# PIC32MZ2048EFM144 register map
Registers are 32-bit, access not given, reset 0x0 unless marked. A register's access mark holds for its fields unless they carry their own. Offsets are from the block's base; [hi:lo] are bit positions; 'fields as' and 'values as' point back to an identical list.

## TMR6 — TMR6 peripheral
Base 0xBF840A00
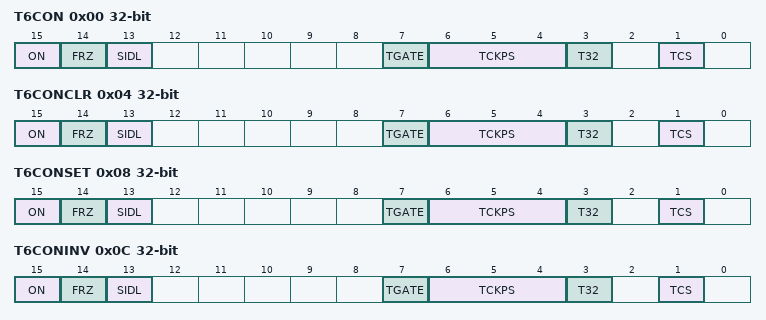
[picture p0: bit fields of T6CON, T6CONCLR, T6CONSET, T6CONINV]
0x00 T6CON
  [15] ON, [14] FRZ, [13] SIDL, [7] TGATE, [6:4] TCKPS, [3] T32, [1] TCS
0x04 T6CONCLR
  fields as T6CON
0x08 T6CONSET
  fields as T6CON
0x0C T6CONINV
  fields as T6CON
0x10 TMR6
0x14 TMR6CLR
  [31:0] TMR6
0x18 TMR6SET
  [31:0] TMR6
0x1C TMR6INV
  [31:0] TMR6
0x20 PR6 reset 0xFFFF
0x24 PR6CLR
  [31:0] PR6
0x28 PR6SET
  [31:0] PR6
0x2C PR6INV
  [31:0] PR6

## TMR7 — TMR7 peripheral
Base 0xBF840C00
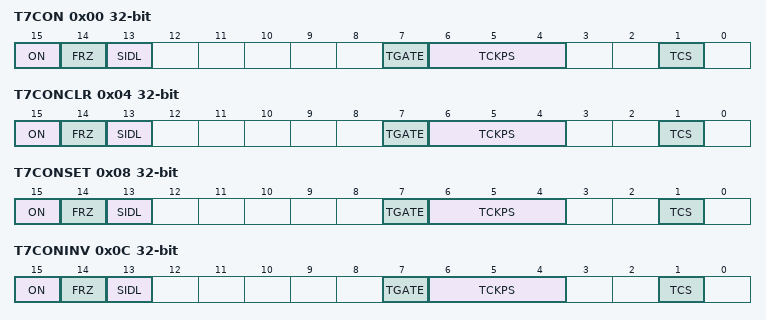
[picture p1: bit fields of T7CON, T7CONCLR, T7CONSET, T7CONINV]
0x00 T7CON
  [15] ON, [14] FRZ, [13] SIDL, [7] TGATE, [6:4] TCKPS, [1] TCS
0x04 T7CONCLR
  [15] ON, [14] FRZ, [13] SIDL, [7] TGATE, [6:4] TCKPS, [1] TCS
0x08 T7CONSET
  [15] ON, [14] FRZ, [13] SIDL, [7] TGATE, [6:4] TCKPS, [1] TCS
0x0C T7CONINV
  [15] ON, [14] FRZ, [13] SIDL, [7] TGATE, [6:4] TCKPS, [1] TCS
0x10 TMR7
0x14 TMR7CLR
  [31:0] TMR7
0x18 TMR7SET
  [31:0] TMR7
0x1C TMR7INV
  [31:0] TMR7
0x20 PR7 reset 0xFFFF
0x24 PR7CLR
  [31:0] PR7
0x28 PR7SET
  [31:0] PR7
0x2C PR7INV
  [31:0] PR7

## TMR8 — TMR8 peripheral
Base 0xBF840E00
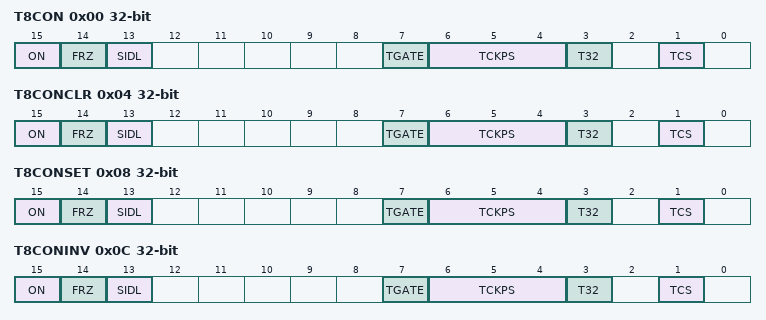
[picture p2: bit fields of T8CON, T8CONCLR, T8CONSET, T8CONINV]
0x00 T8CON
  [15] ON, [14] FRZ, [13] SIDL, [7] TGATE, [6:4] TCKPS, [3] T32, [1] TCS
0x04 T8CONCLR
  fields as T8CON
0x08 T8CONSET
  fields as T8CON
0x0C T8CONINV
  fields as T8CON
0x10 TMR8
0x14 TMR8CLR
  [31:0] TMR8
0x18 TMR8SET
  [31:0] TMR8
0x1C TMR8INV
  [31:0] TMR8
0x20 PR8 reset 0xFFFF
0x24 PR8CLR
  [31:0] PR8
0x28 PR8SET
  [31:0] PR8
0x2C PR8INV
  [31:0] PR8

## TMR9 — TMR9 peripheral
Base 0xBF841000
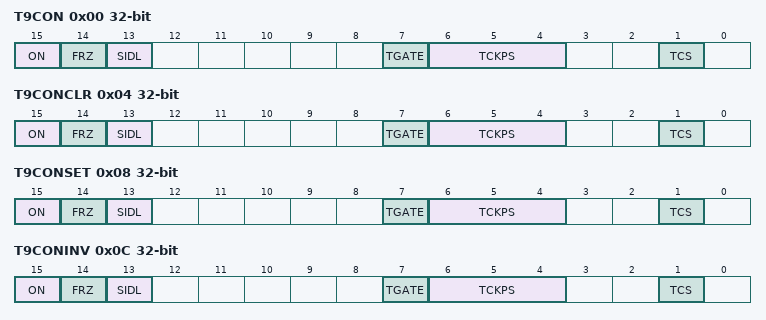
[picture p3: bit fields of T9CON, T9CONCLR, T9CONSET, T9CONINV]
0x00 T9CON
  [15] ON, [14] FRZ, [13] SIDL, [7] TGATE, [6:4] TCKPS, [1] TCS
0x04 T9CONCLR
  [15] ON, [14] FRZ, [13] SIDL, [7] TGATE, [6:4] TCKPS, [1] TCS
0x08 T9CONSET
  [15] ON, [14] FRZ, [13] SIDL, [7] TGATE, [6:4] TCKPS, [1] TCS
0x0C T9CONINV
  [15] ON, [14] FRZ, [13] SIDL, [7] TGATE, [6:4] TCKPS, [1] TCS
0x10 TMR9
0x14 TMR9CLR
  [31:0] TMR9
0x18 TMR9SET
  [31:0] TMR9
0x1C TMR9INV
  [31:0] TMR9
0x20 PR9 reset 0xFFFF
0x24 PR9CLR
  [31:0] PR9
0x28 PR9SET
  [31:0] PR9
0x2C PR9INV
  [31:0] PR9

## ICAP1 — ICAP1 peripheral
Base 0xBF842000
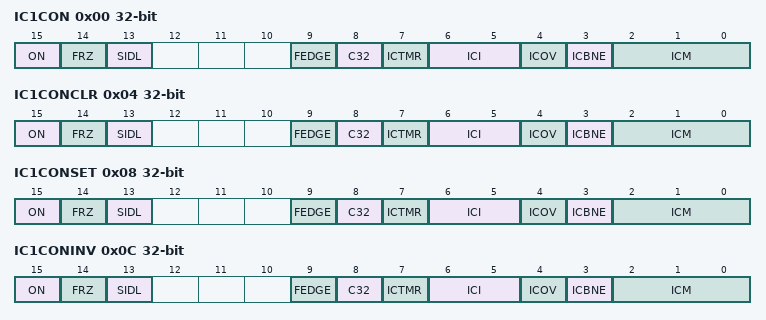
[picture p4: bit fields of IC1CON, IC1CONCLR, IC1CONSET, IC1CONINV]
0x00 IC1CON
  [15] ON, [14] FRZ, [13] SIDL, [9] FEDGE, [8] C32, [7] ICTMR, [6:5] ICI, [4] ICOV, [3] ICBNE, [2:0] ICM
0x04 IC1CONCLR
  fields as IC1CON
0x08 IC1CONSET
  fields as IC1CON
0x0C IC1CONINV
  fields as IC1CON
0x10 IC1BUF

## ICAP2 — ICAP2 peripheral
Base 0xBF842200
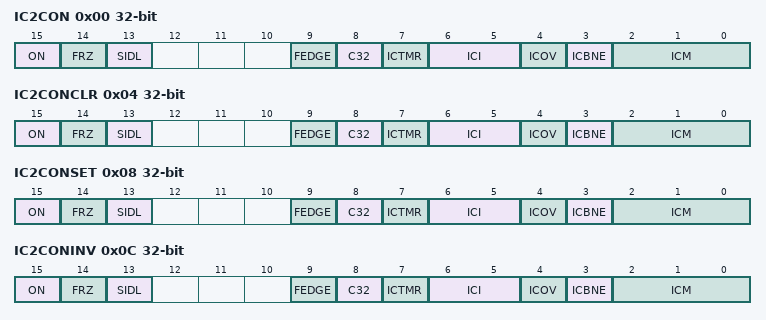
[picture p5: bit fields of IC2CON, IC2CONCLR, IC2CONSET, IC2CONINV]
0x00 IC2CON
  [15] ON, [14] FRZ, [13] SIDL, [9] FEDGE, [8] C32, [7] ICTMR, [6:5] ICI, [4] ICOV, [3] ICBNE, [2:0] ICM
0x04 IC2CONCLR
  fields as IC2CON
0x08 IC2CONSET
  fields as IC2CON
0x0C IC2CONINV
  fields as IC2CON
0x10 IC2BUF

## ICAP3 — ICAP3 peripheral
Base 0xBF842400
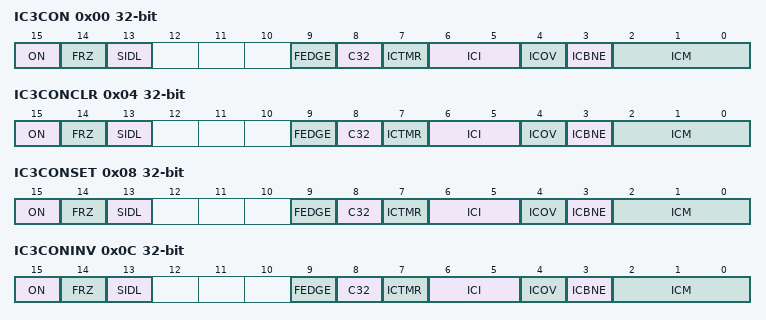
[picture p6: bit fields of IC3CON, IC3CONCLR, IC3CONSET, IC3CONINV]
0x00 IC3CON
  [15] ON, [14] FRZ, [13] SIDL, [9] FEDGE, [8] C32, [7] ICTMR, [6:5] ICI, [4] ICOV, [3] ICBNE, [2:0] ICM
0x04 IC3CONCLR
  fields as IC3CON
0x08 IC3CONSET
  fields as IC3CON
0x0C IC3CONINV
  fields as IC3CON
0x10 IC3BUF

## ICAP4 — ICAP4 peripheral
Base 0xBF842600
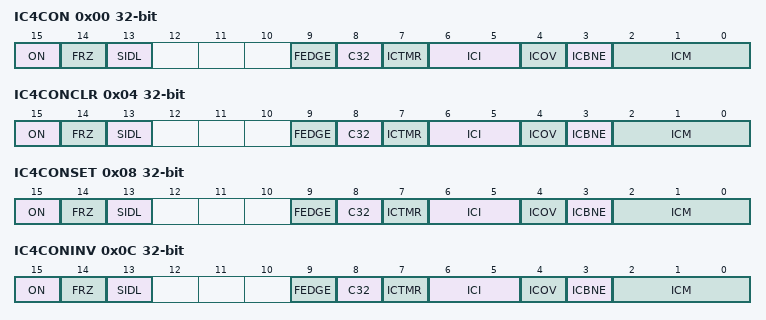
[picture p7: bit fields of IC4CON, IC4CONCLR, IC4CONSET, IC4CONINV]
0x00 IC4CON
  [15] ON, [14] FRZ, [13] SIDL, [9] FEDGE, [8] C32, [7] ICTMR, [6:5] ICI, [4] ICOV, [3] ICBNE, [2:0] ICM
0x04 IC4CONCLR
  fields as IC4CON
0x08 IC4CONSET
  fields as IC4CON
0x0C IC4CONINV
  fields as IC4CON
0x10 IC4BUF

## ICAP5 — ICAP5 peripheral
Base 0xBF842800
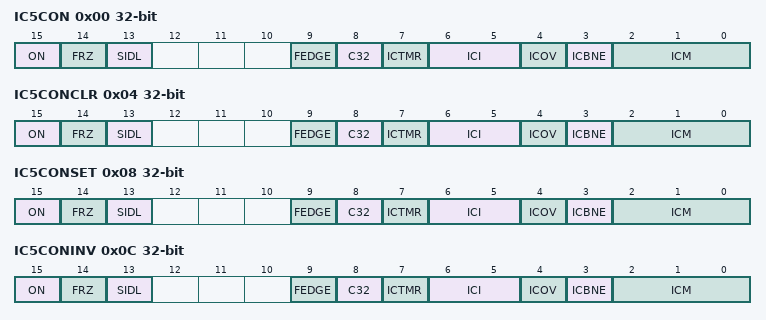
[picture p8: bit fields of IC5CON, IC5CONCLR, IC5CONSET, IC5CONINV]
0x00 IC5CON
  [15] ON, [14] FRZ, [13] SIDL, [9] FEDGE, [8] C32, [7] ICTMR, [6:5] ICI, [4] ICOV, [3] ICBNE, [2:0] ICM
0x04 IC5CONCLR
  fields as IC5CON
0x08 IC5CONSET
  fields as IC5CON
0x0C IC5CONINV
  fields as IC5CON
0x10 IC5BUF

## ICAP6 — ICAP6 peripheral
Base 0xBF842A00
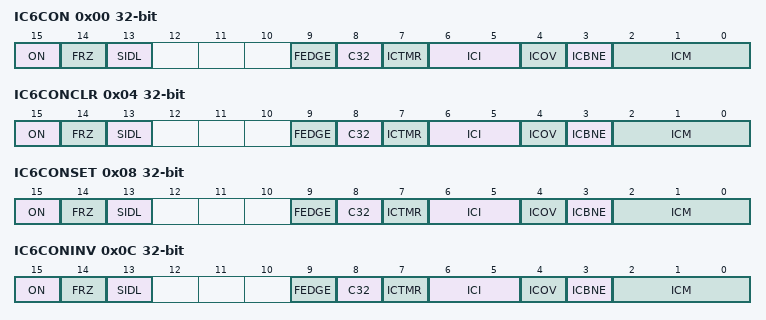
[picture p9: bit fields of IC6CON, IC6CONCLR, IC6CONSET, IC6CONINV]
0x00 IC6CON
  [15] ON, [14] FRZ, [13] SIDL, [9] FEDGE, [8] C32, [7] ICTMR, [6:5] ICI, [4] ICOV, [3] ICBNE, [2:0] ICM
0x04 IC6CONCLR
  fields as IC6CON
0x08 IC6CONSET
  fields as IC6CON
0x0C IC6CONINV
  fields as IC6CON
0x10 IC6BUF
